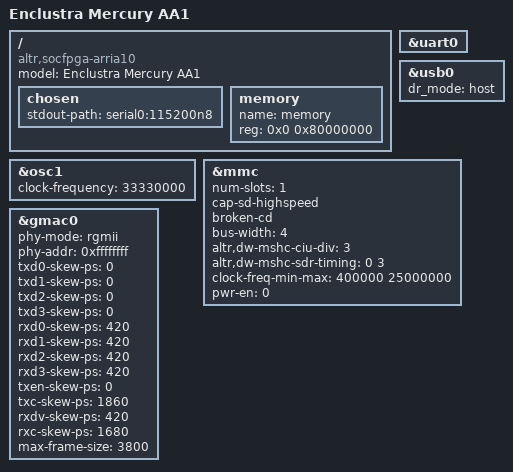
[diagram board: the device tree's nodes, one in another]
/dts-v1/;
#include "socfpga_arria10.dtsi"

/ {
	model = "Enclustra Mercury AA1";
	compatible = "altr,socfpga-arria10", "altr,socfpga";

	chosen {
		stdout-path = "serial0:115200n8";
	};

	memory {
		name = "memory";
		device_type = "memory";
		reg = <0x0 0x80000000>; /* 2GB */
	};
};

&osc1 {
	clock-frequency = <33330000>;
};

&uart0 {
	status = "okay";
};

&usb0 {
	status = "okay";
	dr_mode = "host";
};

/* Following mappings are taken from arria10 socdk dts */
&mmc {
	status = "okay";
	num-slots = <1>;
	cap-sd-highspeed;
	broken-cd;
	bus-width = <4>;
	altr,dw-mshc-ciu-div = <3>;
	altr,dw-mshc-sdr-timing = <0 3>;
	clock-freq-min-max = <400000 25000000>;
	pwr-en = <0>;
};

&gmac0 {
	phy-mode = "rgmii";
	phy-addr = <0xffffffff>; /* probe for phy addr */

	txd0-skew-ps = <0>; /* -420ps */
	txd1-skew-ps = <0>; /* -420ps */
	txd2-skew-ps = <0>; /* -420ps */
	txd3-skew-ps = <0>; /* -420ps */
	rxd0-skew-ps = <420>; /* 0ps */
	rxd1-skew-ps = <420>; /* 0ps */
	rxd2-skew-ps = <420>; /* 0ps */
	rxd3-skew-ps = <420>; /* 0ps */
	txen-skew-ps = <0>; /* -420ps */
	txc-skew-ps = <1860>; /* 960ps */
	rxdv-skew-ps = <420>; /* 0ps */
	rxc-skew-ps = <1680>; /* 780ps */
	max-frame-size = <3800>;
	status = "okay";
};
